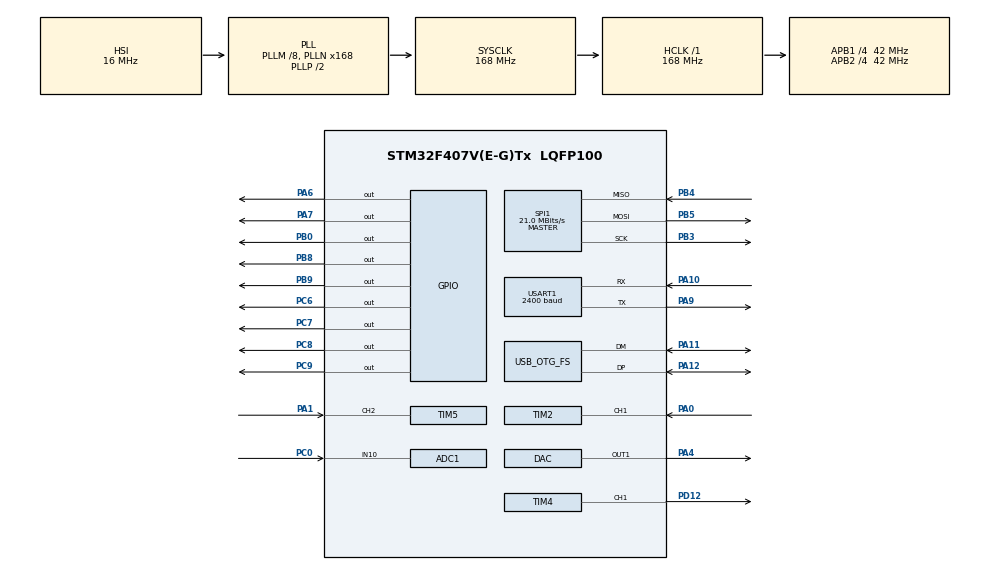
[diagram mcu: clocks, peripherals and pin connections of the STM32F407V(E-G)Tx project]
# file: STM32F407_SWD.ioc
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ADC1.Channel-11\#ChannelRegularConversion=ADC_CHANNEL_10
ADC1.NbrOfConversionFlag=1
ADC1.Rank-11\#ChannelRegularConversion=1
ADC1.SamplingTime-11\#ChannelRegularConversion=ADC_SAMPLETIME_3CYCLES
ADC1.master=1
FATFS._CODE_PAGE=936
FATFS._STRF_ENCODE=0
FATFS._USE_LFN=3
Mcu.Family=STM32F4
Mcu.Name=STM32F407V(E-G)Tx
Mcu.Package=LQFP100
NVIC.OTG_FS_IRQn=true\:0\:0\:false\:false\:true\:false
NVIC.PriorityGroup=NVIC_PRIORITYGROUP_4
NVIC.TIM2_IRQn=true\:0\:0\:false\:false\:true\:true
NVIC.TIM5_IRQn=true\:0\:0\:false\:false\:true\:true
NVIC.USART1_IRQn=true\:3\:0\:true\:false\:true\:true
PA0-WKUP.Signal=S_TIM2_CH1_ETR
PA1.Signal=S_TIM5_CH2
PA10.Mode=Asynchronous
PA10.Signal=USART1_RX
PA11.Mode=Device_Only
PA11.Signal=USB_OTG_FS_DM
PA12.Mode=Device_Only
PA12.Signal=USB_OTG_FS_DP
PA4.Signal=COMP_DAC1_group
PA6.GPIO_PuPd=GPIO_NOPULL
PA6.PinState=GPIO_PIN_SET
PA6.Signal=GPIO_Output
PA7.PinState=GPIO_PIN_SET
PA7.Signal=GPIO_Output
PA9.Mode=Asynchronous
PA9.Signal=USART1_TX
PB0.Signal=GPIO_Output
PB3.Mode=Full_Duplex_Master
PB3.Signal=SPI1_SCK
PB4.Mode=Full_Duplex_Master
PB4.Signal=SPI1_MISO
PB5.Mode=Full_Duplex_Master
PB5.Signal=SPI1_MOSI
PB8.GPIO_PuPd=GPIO_PULLUP
PB8.Signal=GPIO_Output
PB9.GPIO_PuPd=GPIO_PULLDOWN
PB9.Signal=GPIO_Output
PC0.Signal=ADCx_IN10
PC6.Signal=GPIO_Output
PC7.Signal=GPIO_Output
PC8.Signal=GPIO_Output
PC9.Signal=GPIO_Output
PD12.Signal=S_TIM4_CH1
ProjectManager.HeapSize=0xA000
ProjectManager.StackSize=0x5000
ProjectManager.TargetToolchain=MDK-ARM V5
RCC.48MHZClocksFreq_Value=48000000
RCC.AHBFreq_Value=168000000
RCC.APB1CLKDivider=RCC_HCLK_DIV4
RCC.APB1Freq_Value=42000000
RCC.APB1TimFreq_Value=84000000
RCC.APB2CLKDivider=RCC_HCLK_DIV4
RCC.APB2Freq_Value=42000000
RCC.APB2TimFreq_Value=84000000
RCC.CortexFreq_Value=168000000
RCC.HCLKFreq_Value=168000000
RCC.HSE_VALUE=25000000
RCC.HSI_VALUE=16000000
RCC.LSE_VALUE=32768
RCC.PLLM=8
RCC.PLLN=168
RCC.PLLQ=7
RCC.PLLSource=RCC_PLLSOURCE_HSI
RCC.PLLSourceVirtualString=RCC_PLLSOURCE_HSI
RCC.SYSCLKFreq_VALUE=168000000
RCC.SYSCLKSource=RCC_SYSCLKSOURCE_PLLCLK
RCC.VCOOutputFreq_Value=336000000
SH.ADCx_IN10.0=ADC1_IN10,IN10
SH.COMP_DAC1_group.0=DAC_OUT1,DAC_OUT1
SH.S_TIM2_CH1_ETR.0=TIM2_CH1,Input_Capture1_from_TI1
SH.S_TIM4_CH1.0=TIM4_CH1,Output Compare1 CH1
SH.S_TIM5_CH2.0=TIM5_CH2,Input_Capture2_from_TI2
SPI1.BaudRatePrescaler=SPI_BAUDRATEPRESCALER_2
SPI1.CalculateBaudRate=21.0 MBits/s
SPI1.Direction=SPI_DIRECTION_2LINES
SPI1.Mode=SPI_MODE_MASTER
SPI1.VirtualType=VM_MASTER
TIM2.Channel-Input_Capture1_from_TI1=TIM_CHANNEL_1
TIM2.Period=0xffff
TIM2.Prescaler=84
TIM2.TIM_MasterOutputTrigger=TIM_TRGO_RESET
TIM4.Channel-Output\ Compare1\ CH1=TIM_CHANNEL_1
TIM4.Period=4166
TIM4.Prescaler=84
TIM5.Channel-Input_Capture2_from_TI2=TIM_CHANNEL_2
TIM5.Period=0xFFFF
TIM5.Prescaler=84
TIM5.TIM_MasterOutputTrigger=TIM_TRGO_UPDATE
USART1.BaudRate=2400
USART1.VirtualMode=VM_ASYNC
USB_DEVICE.CLASS_NAME_FS=MSC
USB_DEVICE.VirtualMode-MSC_FS=Msc
USB_DEVICE.VirtualModeFS=Msc_FS
USB_OTG_FS.VirtualMode=Device_Only
VP_FATFS_VS_Generic.Mode=User_defined
VP_TIM2_VS_ClockSourceINT.Mode=Internal
VP_TIM5_VS_ClockSourceINT.Mode=Internal
VP_USB_DEVICE_VS_USB_DEVICE_MSC_FS.Mode=MSC_FS
board=STM32F407_SWD

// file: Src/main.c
/**
  ******************************************************************************
  * @file           : main.c
  * @brief          : Main program body
  ******************************************************************************
  * This notice applies to any and all portions of this file
  * that are not between comment pairs USER CODE BEGIN and
  * USER CODE END. Other portions of this file, whether
  * inserted by the user or by software development tools
  * are owned by their respective copyright owners.
  *
  * Copyright (c) 2018 STMicroelectronics International N.V.
  * All rights reserved.
  *
  * Redistribution and use in source and binary forms, with or without
  * modification, are permitted, provided that the following conditions are met:
  *
  * 1. Redistribution of source code must retain the above copyright notice,
  *    this list of conditions and the following disclaimer.
  * 2. Redistributions in binary form must reproduce the above copyright notice,
  *    this list of conditions and the following disclaimer in the documentation
  *    and/or other materials provided with the distribution.
  * 3. Neither the name of STMicroelectronics nor the names of other
  *    contributors to this software may be used to endorse or promote products
  *    derived from this software without specific written permission.
  * 4. This software, including modifications and/or derivative works of this
  *    software, must execute solely and exclusively on microcontroller or
  *    microprocessor devices manufactured by or for STMicroelectronics.
  * 5. Redistribution and use of this software other than as permitted under
  *    this license is void and will automatically terminate your rights under
  *    this license.
  *
  * THIS SOFTWARE IS PROVIDED BY STMICROELECTRONICS AND CONTRIBUTORS "AS IS"
  * AND ANY EXPRESS, IMPLIED OR STATUTORY WARRANTIES, INCLUDING, BUT NOT
  * LIMITED TO, THE IMPLIED WARRANTIES OF MERCHANTABILITY, FITNESS FOR A
  * PARTICULAR PURPOSE AND NON-INFRINGEMENT OF THIRD PARTY INTELLECTUAL PROPERTY
  * RIGHTS ARE DISCLAIMED TO THE FULLEST EXTENT PERMITTED BY LAW. IN NO EVENT
  * SHALL STMICROELECTRONICS OR CONTRIBUTORS BE LIABLE FOR ANY DIRECT, INDIRECT,
  * INCIDENTAL, SPECIAL, EXEMPLARY, OR CONSEQUENTIAL DAMAGES (INCLUDING, BUT NOT
  * LIMITED TO, PROCUREMENT OF SUBSTITUTE GOODS OR SERVICES; LOSS OF USE, DATA,
  * OR PROFITS; OR BUSINESS INTERRUPTION) HOWEVER CAUSED AND ON ANY THEORY OF
  * LIABILITY, WHETHER IN CONTRACT, STRICT LIABILITY, OR TORT (INCLUDING
  * NEGLIGENCE OR OTHERWISE) ARISING IN ANY WAY OUT OF THE USE OF THIS SOFTWARE,
  * EVEN IF ADVISED OF THE POSSIBILITY OF SUCH DAMAGE.
  *
  ******************************************************************************
  */
#include "main.h"
#include "stm32f4xx_hal.h"
#include "fatfs.h"
#include "usb_device.h"

/* USER CODE BEGIN Includes */
#include "sfud.h"
#include "command.h"
#include "target_internal.h"
#include "cortexm.h"
#include "prog_stm32.h"
#include "inverter_test.h"
/* USER CODE END Includes */

ADC_HandleTypeDef hadc1;

DAC_HandleTypeDef hdac;

SPI_HandleTypeDef hspi1;

TIM_HandleTypeDef htim2;
TIM_HandleTypeDef htim4;
TIM_HandleTypeDef htim5;

UART_HandleTypeDef huart1;

/* USER CODE BEGIN PV */
/* Private variables ---------------------------------------------------------*/
sfud_flash *hflash1;
/* USER CODE END PV */

void SystemClock_Config(void);
static void MX_GPIO_Init(void);
static void MX_USART1_UART_Init(void);
static void MX_SPI1_Init(void);
static void MX_TIM2_Init(void);
static void MX_TIM5_Init(void);
static void MX_DAC_Init(void);
static void MX_ADC1_Init(void);
static void MX_TIM4_Init(void);

void HAL_TIM_MspPostInit(TIM_HandleTypeDef *htim);

/* USER CODE BEGIN PFP */
/* Private function prototypes -----------------------------------------------*/

/* USER CODE END PFP */

int main(void)
{

  /* MCU Configuration----------------------------------------------------------*/

  /* Reset of all peripherals, Initializes the Flash interface and the Systick. */
  HAL_Init();

  /* Configure the system clock */
  SystemClock_Config();

  /* Initialize all configured peripherals */
  MX_GPIO_Init();
  MX_USART1_UART_Init();
  MX_SPI1_Init();
  MX_USB_DEVICE_Init();
  MX_FATFS_Init();
  MX_TIM2_Init();
  MX_TIM5_Init();
  MX_DAC_Init();
  MX_ADC1_Init();
  MX_TIM4_Init();
  /* USER CODE BEGIN 2 */
	sfud_init();
	hflash1 = sfud_get_device(0);
	//sfud_erase_write(hflash1, 0, 0x1000, "Hello, World!");
	//sfud_chip_erase(hflash1);

//	uint8_t progStatus = prog_stm32_use_fatfs(0x800);

//MX_USB_DEVICE_Init();

	TEST_Init();

  /* USER CODE END 2 */

  /* Infinite loop */
  /* USER CODE BEGIN WHILE */
  while (1)
  {
	TEST_Proc();
  /* USER CODE END WHILE */

  }

}

void SystemClock_Config(void)
{

  RCC_OscInitTypeDef RCC_OscInitStruct;
  RCC_ClkInitTypeDef RCC_ClkInitStruct;

    /**Configure the main internal regulator output voltage
    */
  __HAL_RCC_PWR_CLK_ENABLE();

  __HAL_PWR_VOLTAGESCALING_CONFIG(PWR_REGULATOR_VOLTAGE_SCALE1);

    /**Initializes the CPU, AHB and APB busses clocks
    */
  RCC_OscInitStruct.OscillatorType = RCC_OSCILLATORTYPE_HSI;
  RCC_OscInitStruct.HSIState = RCC_HSI_ON;
  RCC_OscInitStruct.HSICalibrationValue = 16;
  RCC_OscInitStruct.PLL.PLLState = RCC_PLL_ON;
  RCC_OscInitStruct.PLL.PLLSource = RCC_PLLSOURCE_HSI;
  RCC_OscInitStruct.PLL.PLLM = 8;
  RCC_OscInitStruct.PLL.PLLN = 168;
  RCC_OscInitStruct.PLL.PLLP = RCC_PLLP_DIV2;
  RCC_OscInitStruct.PLL.PLLQ = 7;
  if (HAL_RCC_OscConfig(&RCC_OscInitStruct) != HAL_OK)
  {
    _Error_Handler(__FILE__, __LINE__);
  }

    /**Initializes the CPU, AHB and APB busses clocks
    */
  RCC_ClkInitStruct.ClockType = RCC_CLOCKTYPE_HCLK|RCC_CLOCKTYPE_SYSCLK
                              |RCC_CLOCKTYPE_PCLK1|RCC_CLOCKTYPE_PCLK2;
  RCC_ClkInitStruct.SYSCLKSource = RCC_SYSCLKSOURCE_PLLCLK;
  RCC_ClkInitStruct.AHBCLKDivider = RCC_SYSCLK_DIV1;
  RCC_ClkInitStruct.APB1CLKDivider = RCC_HCLK_DIV4;
  RCC_ClkInitStruct.APB2CLKDivider = RCC_HCLK_DIV4;

  if (HAL_RCC_ClockConfig(&RCC_ClkInitStruct, FLASH_LATENCY_5) != HAL_OK)
  {
    _Error_Handler(__FILE__, __LINE__);
  }

    /**Configure the Systick interrupt time
    */
  HAL_SYSTICK_Config(HAL_RCC_GetHCLKFreq()/1000);

    /**Configure the Systick
    */
  HAL_SYSTICK_CLKSourceConfig(SYSTICK_CLKSOURCE_HCLK);

  /* SysTick_IRQn interrupt configuration */
  HAL_NVIC_SetPriority(SysTick_IRQn, 0, 0);
}

/* ADC1 init function */
static void MX_ADC1_Init(void)
{

  ADC_ChannelConfTypeDef sConfig;

    /**Configure the global features of the ADC (Clock, Resolution, Data Alignment and number of conversion)
    */
  hadc1.Instance = ADC1;
  hadc1.Init.ClockPrescaler = ADC_CLOCK_SYNC_PCLK_DIV2;
  hadc1.Init.Resolution = ADC_RESOLUTION_12B;
  hadc1.Init.ScanConvMode = DISABLE;
  hadc1.Init.ContinuousConvMode = DISABLE;
  hadc1.Init.DiscontinuousConvMode = DISABLE;
  hadc1.Init.ExternalTrigConvEdge = ADC_EXTERNALTRIGCONVEDGE_NONE;
  hadc1.Init.ExternalTrigConv = ADC_SOFTWARE_START;
  hadc1.Init.DataAlign = ADC_DATAALIGN_RIGHT;
  hadc1.Init.NbrOfConversion = 1;
  hadc1.Init.DMAContinuousRequests = DISABLE;
  hadc1.Init.EOCSelection = ADC_EOC_SINGLE_CONV;
  if (HAL_ADC_Init(&hadc1) != HAL_OK)
  {
    _Error_Handler(__FILE__, __LINE__);
  }

    /**Configure for the selected ADC regular channel its corresponding rank in the sequencer and its sample time.
    */
  sConfig.Channel = ADC_CHANNEL_10;
  sConfig.Rank = 1;
  sConfig.SamplingTime = ADC_SAMPLETIME_3CYCLES;
  if (HAL_ADC_ConfigChannel(&hadc1, &sConfig) != HAL_OK)
  {
    _Error_Handler(__FILE__, __LINE__);
  }

}

/* DAC init function */
static void MX_DAC_Init(void)
{

  DAC_ChannelConfTypeDef sConfig;

    /**DAC Initialization
    */
  hdac.Instance = DAC;
  if (HAL_DAC_Init(&hdac) != HAL_OK)
  {
    _Error_Handler(__FILE__, __LINE__);
  }

    /**DAC channel OUT1 config
    */
  sConfig.DAC_Trigger = DAC_TRIGGER_NONE;
  sConfig.DAC_OutputBuffer = DAC_OUTPUTBUFFER_ENABLE;
  if (HAL_DAC_ConfigChannel(&hdac, &sConfig, DAC_CHANNEL_1) != HAL_OK)
  {
    _Error_Handler(__FILE__, __LINE__);
  }

}

/* SPI1 init function */
static void MX_SPI1_Init(void)
{

  /* SPI1 parameter configuration*/
  hspi1.Instance = SPI1;
  hspi1.Init.Mode = SPI_MODE_MASTER;
  hspi1.Init.Direction = SPI_DIRECTION_2LINES;
  hspi1.Init.DataSize = SPI_DATASIZE_8BIT;
  hspi1.Init.CLKPolarity = SPI_POLARITY_LOW;
  hspi1.Init.CLKPhase = SPI_PHASE_1EDGE;
  hspi1.Init.NSS = SPI_NSS_SOFT;
  hspi1.Init.BaudRatePrescaler = SPI_BAUDRATEPRESCALER_2;
  hspi1.Init.FirstBit = SPI_FIRSTBIT_MSB;
  hspi1.Init.TIMode = SPI_TIMODE_DISABLE;
  hspi1.Init.CRCCalculation = SPI_CRCCALCULATION_DISABLE;
  hspi1.Init.CRCPolynomial = 10;
  if (HAL_SPI_Init(&hspi1) != HAL_OK)
  {
    _Error_Handler(__FILE__, __LINE__);
  }

}

/* TIM2 init function */
static void MX_TIM2_Init(void)
{

  TIM_ClockConfigTypeDef sClockSourceConfig;
  TIM_MasterConfigTypeDef sMasterConfig;
  TIM_IC_InitTypeDef sConfigIC;

  htim2.Instance = TIM2;
  htim2.Init.Prescaler = 84;
  htim2.Init.CounterMode = TIM_COUNTERMODE_UP;
  htim2.Init.Period = 0xffff;
  htim2.Init.ClockDivision = TIM_CLOCKDIVISION_DIV1;
  if (HAL_TIM_Base_Init(&htim2) != HAL_OK)
  {
    _Error_Handler(__FILE__, __LINE__);
  }

  sClockSourceConfig.ClockSource = TIM_CLOCKSOURCE_INTERNAL;
  if (HAL_TIM_ConfigClockSource(&htim2, &sClockSourceConfig) != HAL_OK)
  {
    _Error_Handler(__FILE__, __LINE__);
  }

  if (HAL_TIM_IC_Init(&htim2) != HAL_OK)
  {
    _Error_Handler(__FILE__, __LINE__);
  }

  sMasterConfig.MasterOutputTrigger = TIM_TRGO_RESET;
  sMasterConfig.MasterSlaveMode = TIM_MASTERSLAVEMODE_DISABLE;
  if (HAL_TIMEx_MasterConfigSynchronization(&htim2, &sMasterConfig) != HAL_OK)
  {
    _Error_Handler(__FILE__, __LINE__);
  }

  sConfigIC.ICPolarity = TIM_INPUTCHANNELPOLARITY_RISING;
  sConfigIC.ICSelection = TIM_ICSELECTION_DIRECTTI;
  sConfigIC.ICPrescaler = TIM_ICPSC_DIV1;
  sConfigIC.ICFilter = 0;
  if (HAL_TIM_IC_ConfigChannel(&htim2, &sConfigIC, TIM_CHANNEL_1) != HAL_OK)
  {
    _Error_Handler(__FILE__, __LINE__);
  }

}

/* TIM4 init function */
static void MX_TIM4_Init(void)
{

  TIM_MasterConfigTypeDef sMasterConfig;
  TIM_OC_InitTypeDef sConfigOC;

  htim4.Instance = TIM4;
  htim4.Init.Prescaler = 84;
  htim4.Init.CounterMode = TIM_COUNTERMODE_UP;
  htim4.Init.Period = 4166;
  htim4.Init.ClockDivision = TIM_CLOCKDIVISION_DIV1;
  if (HAL_TIM_OC_Init(&htim4) != HAL_OK)
  {
    _Error_Handler(__FILE__, __LINE__);
  }

  sMasterConfig.MasterOutputTrigger = TIM_TRGO_RESET;
  sMasterConfig.MasterSlaveMode = TIM_MASTERSLAVEMODE_DISABLE;
  if (HAL_TIMEx_MasterConfigSynchronization(&htim4, &sMasterConfig) != HAL_OK)
  {
    _Error_Handler(__FILE__, __LINE__);
  }

  sConfigOC.OCMode = TIM_OCMODE_TIMING;
  sConfigOC.Pulse = 0;
  sConfigOC.OCPolarity = TIM_OCPOLARITY_HIGH;
  sConfigOC.OCFastMode = TIM_OCFAST_DISABLE;
  if (HAL_TIM_OC_ConfigChannel(&htim4, &sConfigOC, TIM_CHANNEL_1) != HAL_OK)
  {
    _Error_Handler(__FILE__, __LINE__);
  }

  HAL_TIM_MspPostInit(&htim4);

}

/* TIM5 init function */
static void MX_TIM5_Init(void)
{

  TIM_ClockConfigTypeDef sClockSourceConfig;
  TIM_MasterConfigTypeDef sMasterConfig;
  TIM_IC_InitTypeDef sConfigIC;

  htim5.Instance = TIM5;
  htim5.Init.Prescaler = 84;
  htim5.Init.CounterMode = TIM_COUNTERMODE_UP;
  htim5.Init.Period = 0xFFFF;
  htim5.Init.ClockDivision = TIM_CLOCKDIVISION_DIV1;
  if (HAL_TIM_Base_Init(&htim5) != HAL_OK)
  {
    _Error_Handler(__FILE__, __LINE__);
  }

  sClockSourceConfig.ClockSource = TIM_CLOCKSOURCE_INTERNAL;
  if (HAL_TIM_ConfigClockSource(&htim5, &sClockSourceConfig) != HAL_OK)
  {
    _Error_Handler(__FILE__, __LINE__);
  }

  if (HAL_TIM_IC_Init(&htim5) != HAL_OK)
  {
    _Error_Handler(__FILE__, __LINE__);
  }

  sMasterConfig.MasterOutputTrigger = TIM_TRGO_UPDATE;
  sMasterConfig.MasterSlaveMode = TIM_MASTERSLAVEMODE_DISABLE;
  if (HAL_TIMEx_MasterConfigSynchronization(&htim5, &sMasterConfig) != HAL_OK)
  {
    _Error_Handler(__FILE__, __LINE__);
  }

  sConfigIC.ICPolarity = TIM_INPUTCHANNELPOLARITY_RISING;
  sConfigIC.ICSelection = TIM_ICSELECTION_DIRECTTI;
  sConfigIC.ICPrescaler = TIM_ICPSC_DIV1;
  sConfigIC.ICFilter = 0;
  if (HAL_TIM_IC_ConfigChannel(&htim5, &sConfigIC, TIM_CHANNEL_2) != HAL_OK)
  {
    _Error_Handler(__FILE__, __LINE__);
  }

}

/* USART1 init function */
static void MX_USART1_UART_Init(void)
{

  huart1.Instance = USART1;
  huart1.Init.BaudRate = 2400;
  huart1.Init.WordLength = UART_WORDLENGTH_8B;
  huart1.Init.StopBits = UART_STOPBITS_1;
  huart1.Init.Parity = UART_PARITY_NONE;
  huart1.Init.Mode = UART_MODE_TX_RX;
  huart1.Init.HwFlowCtl = UART_HWCONTROL_NONE;
  huart1.Init.OverSampling = UART_OVERSAMPLING_16;
  if (HAL_UART_Init(&huart1) != HAL_OK)
  {
    _Error_Handler(__FILE__, __LINE__);
  }

}

/** Configure pins as
        * Analog
        * Input
        * Output
        * EVENT_OUT
        * EXTI
*/
static void MX_GPIO_Init(void)
{

  GPIO_InitTypeDef GPIO_InitStruct;

  /* GPIO Ports Clock Enable */
  __HAL_RCC_GPIOC_CLK_ENABLE();
  __HAL_RCC_GPIOA_CLK_ENABLE();
  __HAL_RCC_GPIOB_CLK_ENABLE();
  __HAL_RCC_GPIOD_CLK_ENABLE();

  /*Configure GPIO pin Output Level */
  HAL_GPIO_WritePin(GPIOA, GPIO_PIN_6|GPIO_PIN_7, GPIO_PIN_SET);

  /*Configure GPIO pin Output Level */
  HAL_GPIO_WritePin(GPIOB, GPIO_PIN_0|GPIO_PIN_8|GPIO_PIN_9, GPIO_PIN_RESET);

  /*Configure GPIO pin Output Level */
  HAL_GPIO_WritePin(GPIOC, GPIO_PIN_6|GPIO_PIN_7|GPIO_PIN_8|GPIO_PIN_9, GPIO_PIN_RESET);

  /*Configure GPIO pins : PA6 PA7 */
  GPIO_InitStruct.Pin = GPIO_PIN_6|GPIO_PIN_7;
  GPIO_InitStruct.Mode = GPIO_MODE_OUTPUT_PP;
  GPIO_InitStruct.Pull = GPIO_NOPULL;
  GPIO_InitStruct.Speed = GPIO_SPEED_FREQ_LOW;
  HAL_GPIO_Init(GPIOA, &GPIO_InitStruct);

  /*Configure GPIO pin : PB0 */
  GPIO_InitStruct.Pin = GPIO_PIN_0;
  GPIO_InitStruct.Mode = GPIO_MODE_OUTPUT_PP;
  GPIO_InitStruct.Pull = GPIO_NOPULL;
  GPIO_InitStruct.Speed = GPIO_SPEED_FREQ_LOW;
  HAL_GPIO_Init(GPIOB, &GPIO_InitStruct);

  /*Configure GPIO pins : PC6 PC7 PC8 PC9 */
  GPIO_InitStruct.Pin = GPIO_PIN_6|GPIO_PIN_7|GPIO_PIN_8|GPIO_PIN_9;
  GPIO_InitStruct.Mode = GPIO_MODE_OUTPUT_PP;
  GPIO_InitStruct.Pull = GPIO_NOPULL;
  GPIO_InitStruct.Speed = GPIO_SPEED_FREQ_LOW;
  HAL_GPIO_Init(GPIOC, &GPIO_InitStruct);

  /*Configure GPIO pin : PB8 */
  GPIO_InitStruct.Pin = GPIO_PIN_8;
  GPIO_InitStruct.Mode = GPIO_MODE_OUTPUT_PP;
  GPIO_InitStruct.Pull = GPIO_PULLUP;
  GPIO_InitStruct.Speed = GPIO_SPEED_FREQ_LOW;
  HAL_GPIO_Init(GPIOB, &GPIO_InitStruct);

  /*Configure GPIO pin : PB9 */
  GPIO_InitStruct.Pin = GPIO_PIN_9;
  GPIO_InitStruct.Mode = GPIO_MODE_OUTPUT_PP;
  GPIO_InitStruct.Pull = GPIO_PULLDOWN;
  GPIO_InitStruct.Speed = GPIO_SPEED_FREQ_LOW;
  HAL_GPIO_Init(GPIOB, &GPIO_InitStruct);

}

void _Error_Handler(char *file, int line)
{
  while(1)
  {
  }
}

/************************ (C) COPYRIGHT STMicroelectronics *****END OF FILE****/
